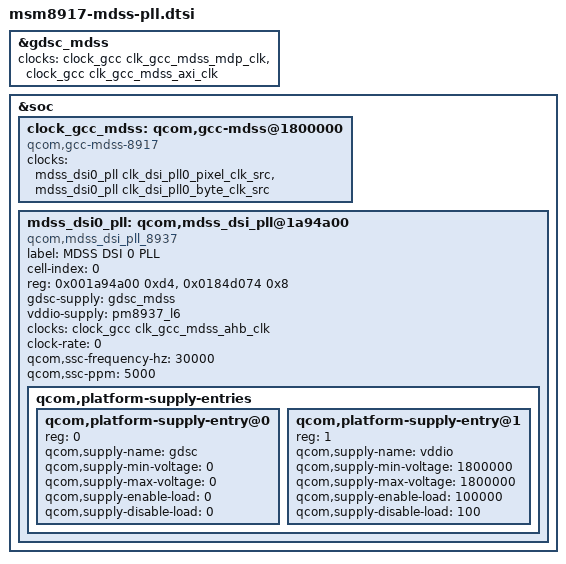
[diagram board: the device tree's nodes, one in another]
/* Copyright (c) 2018, The Linux Foundation. All rights reserved.
 *
 * This program is free software; you can redistribute it and/or modify
 * it under the terms of the GNU General Public License version 2 and
 * only version 2 as published by the Free Software Foundation.
 *
 * This program is distributed in the hope that it will be useful,
 * but WITHOUT ANY WARRANTY; without even the implied warranty of
 * MERCHANTABILITY or FITNESS FOR A PARTICULAR PURPOSE.  See the
 * GNU General Public License for more details.
 */
/*
 * This software is contributed or developed by KYOCERA Corporation.
 * (C) 2019 KYOCERA Corporation
 */

&gdsc_mdss {
	clock-names = "core_clk", "bus_clk";
	clocks = <&clock_gcc clk_gcc_mdss_mdp_clk>,
		 <&clock_gcc clk_gcc_mdss_axi_clk>;
	status = "okay";
};

&soc {
	clock_gcc_mdss: qcom,gcc-mdss@1800000 {
		compatible = "qcom,gcc-mdss-8917";
		clocks = <&mdss_dsi0_pll clk_dsi_pll0_pixel_clk_src>,
		<&mdss_dsi0_pll clk_dsi_pll0_byte_clk_src>;
		clock-names = "pclk0_src", "byte0_src";
		#clock-cells = <1>;
	};

	mdss_dsi0_pll: qcom,mdss_dsi_pll@1a94a00 {
		compatible = "qcom,mdss_dsi_pll_8937";
		label = "MDSS DSI 0 PLL";
		cell-index = <0>;
		#clock-cells = <1>;

		reg = <0x001a94a00 0xd4>,
			<0x0184d074 0x8>;
		reg-names = "pll_base", "gdsc_base";

		gdsc-supply = <&gdsc_mdss>;
		vddio-supply = <&pm8937_l6>;

		clocks = <&clock_gcc clk_gcc_mdss_ahb_clk>;
		clock-names = "iface_clk";
		clock-rate = <0>;
		/delete-property/ qcom,dsi-pll-ssc-en;
		/delete-property/ qcom,dsi-pll-ssc-mode;
		qcom,ssc-frequency-hz = <30000>;
		qcom,ssc-ppm = <5000>;

		qcom,platform-supply-entries {
			#address-cells = <1>;
			#size-cells = <0>;

			qcom,platform-supply-entry@0 {
				reg = <0>;
				qcom,supply-name = "gdsc";
				qcom,supply-min-voltage = <0>;
				qcom,supply-max-voltage = <0>;
				qcom,supply-enable-load = <0>;
				qcom,supply-disable-load = <0>;
			};

			qcom,platform-supply-entry@1 {
				reg = <1>;
				qcom,supply-name = "vddio";
				qcom,supply-min-voltage = <1800000>;
				qcom,supply-max-voltage = <1800000>;
				qcom,supply-enable-load = <100000>;
				qcom,supply-disable-load = <100>;
			};
		};
	};
};
